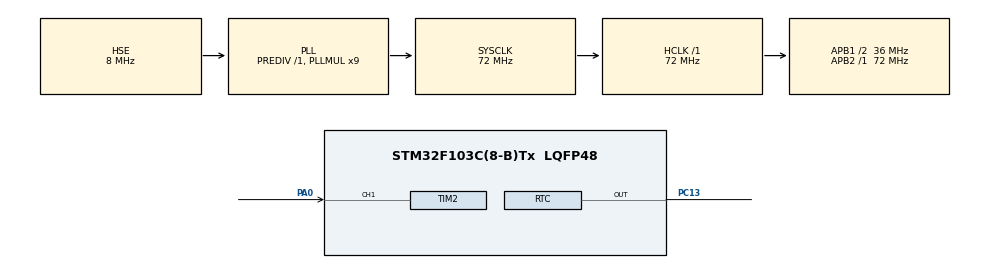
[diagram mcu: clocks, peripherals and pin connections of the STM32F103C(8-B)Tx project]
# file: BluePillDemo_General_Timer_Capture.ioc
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Mcu.Family=STM32F1
Mcu.Name=STM32F103C(8-B)Tx
Mcu.Package=LQFP48
NVIC.PriorityGroup=NVIC_PRIORITYGROUP_4
NVIC.TIM2_IRQn=true\:0\:0\:false\:false\:true\:true\:true
PA0-WKUP.Signal=S_TIM2_CH1_ETR
PA13.Mode=Serial_Wire
PA13.Signal=SYS_JTMS-SWDIO
PA14.Mode=Serial_Wire
PA14.Signal=SYS_JTCK-SWCLK
PC13-TAMPER-RTC.Mode=RTC OUT
PC13-TAMPER-RTC.Signal=RTC_OUT
PC14-OSC32_IN.Mode=LSE-External-Oscillator
PC14-OSC32_IN.Signal=RCC_OSC32_IN
PC15-OSC32_OUT.Mode=LSE-External-Oscillator
PC15-OSC32_OUT.Signal=RCC_OSC32_OUT
PD0-OSC_IN.Mode=HSE-External-Oscillator
PD0-OSC_IN.Signal=RCC_OSC_IN
PD1-OSC_OUT.Mode=HSE-External-Oscillator
PD1-OSC_OUT.Signal=RCC_OSC_OUT
ProjectManager.HeapSize=0x200
ProjectManager.StackSize=0x400
ProjectManager.TargetToolchain=STM32CubeIDE
RCC.AHBFreq_Value=72000000
RCC.APB1CLKDivider=RCC_HCLK_DIV2
RCC.APB1Freq_Value=36000000
RCC.APB1TimFreq_Value=72000000
RCC.APB2Freq_Value=72000000
RCC.APB2TimFreq_Value=72000000
RCC.HCLKFreq_Value=72000000
RCC.PLLMUL=RCC_PLL_MUL9
RCC.PLLSourceVirtual=RCC_PLLSOURCE_HSE
RCC.RCC_MCOSource=RCC_MCO1SOURCE_HSI
RCC.RTCClockSelection=RCC_RTCCLKSOURCE_HSE_DIV128
RCC.SYSCLKFreq_VALUE=72000000
RCC.SYSCLKSource=RCC_SYSCLKSOURCE_PLLCLK
RCC.USBFreq_Value=72000000
RTC.OutPut=RTC_OUTPUTSOURCE_CALIBCLOCK
SH.S_TIM2_CH1_ETR.0=TIM2_CH1,Input_Capture1_from_TI1
TIM2.Channel-Input_Capture1_from_TI1=TIM_CHANNEL_1
TIM2.ClockDivision=TIM_CLOCKDIVISION_DIV4
TIM2.ICPrescaler-Input_Capture1_from_TI1=TIM_ICPSC_DIV1
TIM2.Period=0xffff
TIM2.Prescaler=0
VP_RTC_VS_RTC_Activate.Mode=RTC_Enabled
VP_TIM2_VS_ClockSourceINT.Mode=Internal
board=custom

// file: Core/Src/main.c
/* USER CODE BEGIN Header */
/**
  ******************************************************************************
  * @file           : main.c
  * @brief          : Main program body
  ******************************************************************************
  * @attention
  *
  * <h2><center>&copy; Copyright (c) 2020 STMicroelectronics.
  * All rights reserved.</center></h2>
  *
  * This software component is licensed by ST under BSD 3-Clause license,
  * the "License"; You may not use this file except in compliance with the
  * License. You may obtain a copy of the License at:
  *                        opensource.org/licenses/BSD-3-Clause
  *
  ******************************************************************************
  */
/* USER CODE END Header */

#include "main.h"

/* USER CODE BEGIN Includes */
#include <stdbool.h>

/* USER CODE END Includes */

RTC_HandleTypeDef hrtc;

TIM_HandleTypeDef htim2;

void SystemClock_Config(void);
static void MX_GPIO_Init(void);
static void MX_TIM2_Init(void);
static void MX_RTC_Init(void);

/* USER CODE BEGIN 0 */

void HAL_TIM_IC_CaptureCallback(TIM_HandleTypeDef *htim)
{
  static uint32_t timer_value;
  static uint32_t previous_timer_value;
  static uint32_t first_value = true;
  static uint32_t clock_divider = 4U;
  uint32_t difference;
  uint32_t clock_frequency;
  uint32_t pin_frequency;

  // check if this callback is for channel 1
  if (htim->Channel == HAL_TIM_ACTIVE_CHANNEL_1)
  {
	// read the rimer value at capture
    timer_value = HAL_TIM_ReadCapturedValue(htim, TIM_CHANNEL_1);

    // if first time round we don't have a previous value so don't do calculation
    if (!first_value)
    {
      // not first time round so have a previous value

      // work out difference between 2 subsequent captures; don't know which one will be bigger because of possible rollover
	  if (timer_value > previous_timer_value)
	  {
		difference = timer_value - previous_timer_value;
	  }
	  else
	  {
		difference = ((0xffff - previous_timer_value) + timer_value) + 1U;
	  }

	  // get the capture clock frequency and apply divider
	  clock_frequency = HAL_RCC_GetPCLK1Freq() / clock_divider;

	  // avoid division by zero
	  if (difference != 0U)
	  {
		// calculate the frequency on capture pin using clock frquenct and captured values difference
	    pin_frequency = clock_frequency / difference;
	    (void)pin_frequency;
	  }
    }

    // cache the latest capture value for next time
	previous_timer_value = timer_value;
    first_value = false;
  }
}

/* USER CODE END 0 */

int main(void)
{

  /* MCU Configuration--------------------------------------------------------*/

  /* Reset of all peripherals, Initializes the Flash interface and the Systick. */
  HAL_Init();

  /* Configure the system clock */
  SystemClock_Config();

  /* Initialize all configured peripherals */
  MX_GPIO_Init();
  MX_TIM2_Init();
  MX_RTC_Init();
  /* USER CODE BEGIN 2 */
  HAL_TIM_IC_Start_IT(&htim2, TIM_CHANNEL_1);

  /* USER CODE END 2 */

  /* Infinite loop */
  while (1)
  {

  }
}

void SystemClock_Config(void)
{
  RCC_OscInitTypeDef RCC_OscInitStruct = {0};
  RCC_ClkInitTypeDef RCC_ClkInitStruct = {0};
  RCC_PeriphCLKInitTypeDef PeriphClkInit = {0};

  /** Initializes the CPU, AHB and APB busses clocks
  */
  RCC_OscInitStruct.OscillatorType = RCC_OSCILLATORTYPE_HSE;
  RCC_OscInitStruct.HSEState = RCC_HSE_ON;
  RCC_OscInitStruct.HSEPredivValue = RCC_HSE_PREDIV_DIV1;
  RCC_OscInitStruct.HSIState = RCC_HSI_ON;
  RCC_OscInitStruct.PLL.PLLState = RCC_PLL_ON;
  RCC_OscInitStruct.PLL.PLLSource = RCC_PLLSOURCE_HSE;
  RCC_OscInitStruct.PLL.PLLMUL = RCC_PLL_MUL9;
  if (HAL_RCC_OscConfig(&RCC_OscInitStruct) != HAL_OK)
  {
    Error_Handler();
  }
  /** Initializes the CPU, AHB and APB busses clocks
  */
  RCC_ClkInitStruct.ClockType = RCC_CLOCKTYPE_HCLK|RCC_CLOCKTYPE_SYSCLK
                              |RCC_CLOCKTYPE_PCLK1|RCC_CLOCKTYPE_PCLK2;
  RCC_ClkInitStruct.SYSCLKSource = RCC_SYSCLKSOURCE_PLLCLK;
  RCC_ClkInitStruct.AHBCLKDivider = RCC_SYSCLK_DIV1;
  RCC_ClkInitStruct.APB1CLKDivider = RCC_HCLK_DIV2;
  RCC_ClkInitStruct.APB2CLKDivider = RCC_HCLK_DIV1;

  if (HAL_RCC_ClockConfig(&RCC_ClkInitStruct, FLASH_LATENCY_2) != HAL_OK)
  {
    Error_Handler();
  }
  PeriphClkInit.PeriphClockSelection = RCC_PERIPHCLK_RTC;
  PeriphClkInit.RTCClockSelection = RCC_RTCCLKSOURCE_HSE_DIV128;
  if (HAL_RCCEx_PeriphCLKConfig(&PeriphClkInit) != HAL_OK)
  {
    Error_Handler();
  }
}

static void MX_RTC_Init(void)
{

  RTC_TimeTypeDef sTime = {0};
  RTC_DateTypeDef DateToUpdate = {0};

  /** Initialize RTC Only
  */
  hrtc.Instance = RTC;
  hrtc.Init.AsynchPrediv = RTC_AUTO_1_SECOND;
  hrtc.Init.OutPut = RTC_OUTPUTSOURCE_CALIBCLOCK;
  if (HAL_RTC_Init(&hrtc) != HAL_OK)
  {
    Error_Handler();
  }

  /** Initialize RTC and set the Time and Date
  */
  sTime.Hours = 0x0;
  sTime.Minutes = 0x0;
  sTime.Seconds = 0x0;

  if (HAL_RTC_SetTime(&hrtc, &sTime, RTC_FORMAT_BCD) != HAL_OK)
  {
    Error_Handler();
  }
  DateToUpdate.WeekDay = RTC_WEEKDAY_MONDAY;
  DateToUpdate.Month = RTC_MONTH_JANUARY;
  DateToUpdate.Date = 0x1;
  DateToUpdate.Year = 0x0;

  if (HAL_RTC_SetDate(&hrtc, &DateToUpdate, RTC_FORMAT_BCD) != HAL_OK)
  {
    Error_Handler();
  }

}

static void MX_TIM2_Init(void)
{

  TIM_ClockConfigTypeDef sClockSourceConfig = {0};
  TIM_MasterConfigTypeDef sMasterConfig = {0};
  TIM_IC_InitTypeDef sConfigIC = {0};

  htim2.Instance = TIM2;
  htim2.Init.Prescaler = 0;
  htim2.Init.CounterMode = TIM_COUNTERMODE_UP;
  htim2.Init.Period = 0xffff;
  htim2.Init.ClockDivision = TIM_CLOCKDIVISION_DIV4;
  htim2.Init.AutoReloadPreload = TIM_AUTORELOAD_PRELOAD_DISABLE;
  if (HAL_TIM_Base_Init(&htim2) != HAL_OK)
  {
    Error_Handler();
  }
  sClockSourceConfig.ClockSource = TIM_CLOCKSOURCE_INTERNAL;
  if (HAL_TIM_ConfigClockSource(&htim2, &sClockSourceConfig) != HAL_OK)
  {
    Error_Handler();
  }
  if (HAL_TIM_IC_Init(&htim2) != HAL_OK)
  {
    Error_Handler();
  }
  sMasterConfig.MasterOutputTrigger = TIM_TRGO_RESET;
  sMasterConfig.MasterSlaveMode = TIM_MASTERSLAVEMODE_DISABLE;
  if (HAL_TIMEx_MasterConfigSynchronization(&htim2, &sMasterConfig) != HAL_OK)
  {
    Error_Handler();
  }
  sConfigIC.ICPolarity = TIM_INPUTCHANNELPOLARITY_RISING;
  sConfigIC.ICSelection = TIM_ICSELECTION_DIRECTTI;
  sConfigIC.ICPrescaler = TIM_ICPSC_DIV1;
  sConfigIC.ICFilter = 0;
  if (HAL_TIM_IC_ConfigChannel(&htim2, &sConfigIC, TIM_CHANNEL_1) != HAL_OK)
  {
    Error_Handler();
  }

}

static void MX_GPIO_Init(void)
{

  /* GPIO Ports Clock Enable */
  __HAL_RCC_GPIOC_CLK_ENABLE();
  __HAL_RCC_GPIOD_CLK_ENABLE();
  __HAL_RCC_GPIOA_CLK_ENABLE();

}

void Error_Handler(void)
{
}

/************************ (C) COPYRIGHT STMicroelectronics *****END OF FILE****/
